# RP2040 register map
Vendor: Raspberry Pi; File version: 0.1
CPU: CM0PLUS r0p1, little endian, MPU, no FPU, VTOR, 2 interrupt priority bits, 26 interrupts
Registers are 32-bit, read-write, reset 0x0 unless marked. A register's access mark holds for its fields unless they carry their own. Offsets are from the block's base; [hi:lo] are bit positions; lines under a group give offsets from that group; {n}, {i} and the like mark numbered series; 'fields as' and 'values as' point back to an identical list; <NAME> marks a mode.

## PADS_BANK0
Base 0x4001C000
0x00 VOLTAGE_SELECT — Voltage select. Per bank control
  [0] VOLTAGE_SELECT
    0=3v3 (Set voltage to 3.3V (DVDD >= 2V5)); 1=1v8 (Set voltage to 1.8V (DVDD <= 1V8))
{0x4+4i} GPIO[{i}] (i=0..29) group
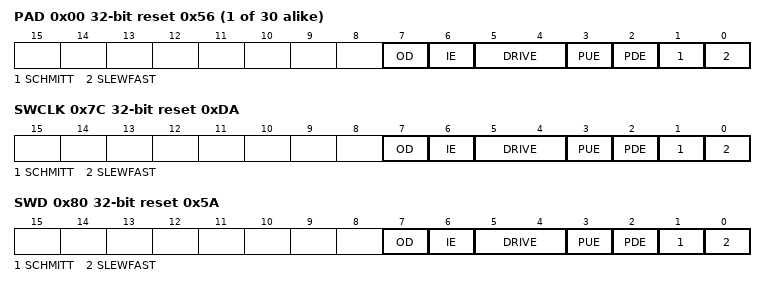
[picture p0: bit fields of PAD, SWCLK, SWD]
  0x00 PAD reset 0x56 — Pad control register
    [7] OD — Output disable. Has priority over output enable from peripherals
    [6] IE — Input enable
    [5:4] DRIVE — Drive strength.
      0=2mA; 1=4mA; 2=8mA; 3=12mA
    [3] PUE — Pull up enable
    [2] PDE — Pull down enable
    [1] SCHMITT — Enable schmitt trigger
    [0] SLEWFAST — Slew rate control. 1 = Fast, 0 = Slow
0x7C SWCLK reset 0xDA — Pad control register
  fields as GPIO[0].PAD
0x80 SWD reset 0x5A — Pad control register
  fields as GPIO[0].PAD

## PADS_QSPI
Base 0x40020000
0x00 VOLTAGE_SELECT — Voltage select. Per bank control
  [0] VOLTAGE_SELECT
    0=3v3 (Set voltage to 3.3V (DVDD >= 2V5)); 1=1v8 (Set voltage to 1.8V (DVDD <= 1V8))
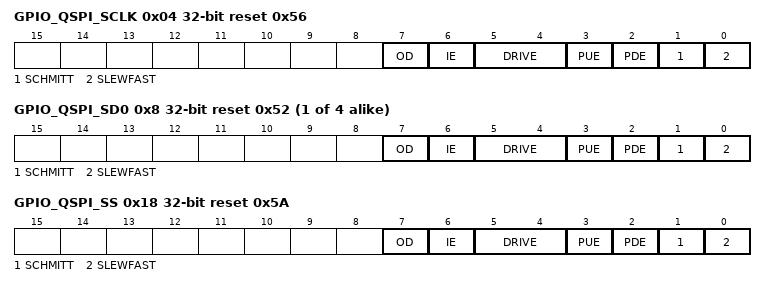
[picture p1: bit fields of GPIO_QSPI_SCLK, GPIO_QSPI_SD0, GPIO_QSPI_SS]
0x04 GPIO_QSPI_SCLK reset 0x56 — Pad control register
  [7] OD — Output disable. Has priority over output enable from peripherals
  [6] IE — Input enable
  [5:4] DRIVE — Drive strength.
    0=2mA; 1=4mA; 2=8mA; 3=12mA
  [3] PUE — Pull up enable
  [2] PDE — Pull down enable
  [1] SCHMITT — Enable schmitt trigger
  [0] SLEWFAST — Slew rate control. 1 = Fast, 0 = Slow
{0x8+4i} GPIO_QSPI_SD{i} reset 0x52 (i=0..3) — Pad control register
  fields as GPIO_QSPI_SCLK
0x18 GPIO_QSPI_SS reset 0x5A — Pad control register
  fields as GPIO_QSPI_SCLK

## XOSC — Controls the crystal oscillator
Base 0x40024000
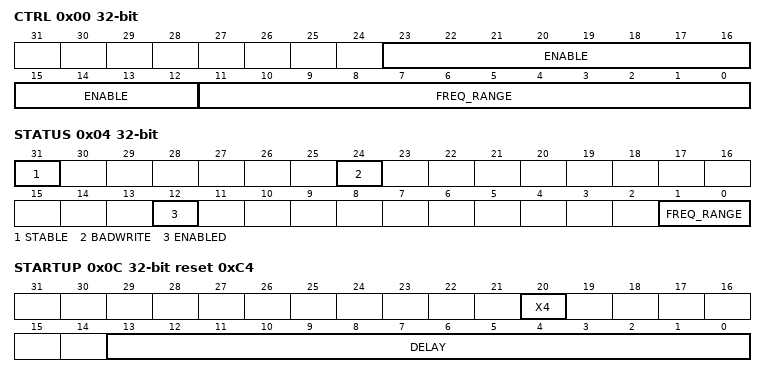
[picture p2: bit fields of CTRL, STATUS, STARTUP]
0x00 CTRL — Crystal Oscillator Control
  [23:12] ENABLE — On power-up this field is initialised to DISABLE and the chip runs from the ROSC. If the chip has subsequently been programmed to run from the XOSC then setting this field to DISABLE may lock-up the chip. If this is a concern then run the clk_ref from the ROSC and enable the clk_sys RESUS feature. The 12-bit code is intended to give some protection against accidental writes. An invalid setting will enable the oscillator.
    0xD1E=DISABLE; 0xFAB=EN
  [11:0] FREQ_RANGE — Frequency range. This resets to 0xAA0 and cannot be changed.
    0xAA0=1_15MHZ
0x04 STATUS access per field — Crystal Oscillator Status
  [31] STABLE ro — Oscillator is running and stable
  [24] BADWRITE rw write-1-clears — An invalid value has been written to CTRL_ENABLE or CTRL_FREQ_RANGE or DORMANT
  [12] ENABLED ro — Oscillator is enabled but not necessarily running and stable, resets to 0
  [1:0] FREQ_RANGE ro — The current frequency range setting, always reads 0
    0=1_15MHZ
0x08 DORMANT — Crystal Oscillator pause control. This is used to save power by pausing the XOSC. On power-up this field is initialised to WAKE. An invalid write will also select WAKE. WARNING: stop the PLLs before selecting dormant mode. WARNING: setup the irq before selecting dormant mode
0x0C STARTUP reset 0xC4 — Controls the startup delay
  [20] X4 — Multiplies the startup_delay by 4. This is of little value to the user given that the delay can be programmed directly.
  [13:0] DELAY — in multiples of 256*xtal_period. The reset value of 0xc4 corresponds to approx 50 000 cycles.
0x1C COUNT — A down counter running at the xosc frequency which counts to zero and stops. To start the counter write a non-zero value. Can be used for short software pauses when setting up time sensitive hardware.
  [7:0] COUNT

## PLL0
Base 0x40028000
Same registers: PLL1 0x4002C000
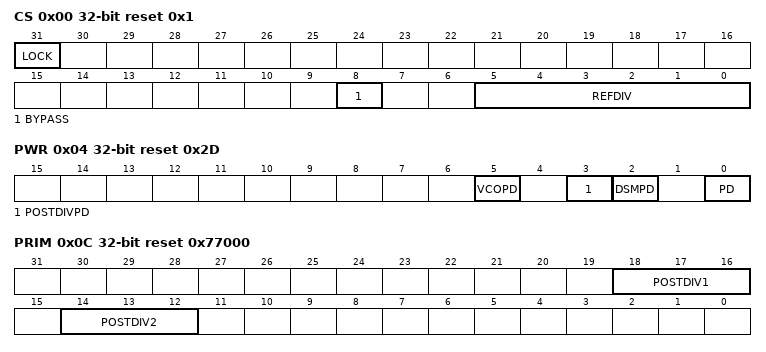
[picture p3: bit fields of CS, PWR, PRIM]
0x00 CS access per field reset 0x1 — Control and Status. GENERAL CONSTRAINTS: Reference clock frequency min=5MHz, max=800MHz. Feedback divider min=16, max=320. VCO frequency min=400MHz, max=1600MHz
  [31] LOCK ro — PLL is locked
  [8] BYPASS rw — Passes the reference clock to the output instead of the divided VCO. The VCO continues to run so the user can switch between the reference clock and the divided VCO but the output will glitch when doing so.
  [5:0] REFDIV rw — Divides the PLL input reference clock. Behaviour is undefined for div=0. PLL output will be unpredictable during refdiv changes, wait for lock=1 before using it.
0x04 PWR reset 0x2D — Controls the PLL power modes.
  [5] VCOPD — PLL VCO powerdown. To save power set high when PLL output not required or bypass=1.
  [3] POSTDIVPD — PLL post divider powerdown. To save power set high when PLL output not required or bypass=1.
  [2] DSMPD — PLL DSM powerdown. Nothing is achieved by setting this low.
  [0] PD — PLL powerdown. To save power set high when PLL output not required.
0x08 FBDIV_INT — Feedback divisor (note: this PLL does not support fractional division)
  [11:0] FBDIV_INT — see ctrl reg description for constraints
0x0C PRIM reset 0x77000 — Controls the PLL post dividers for the primary output (note: this PLL does not have a secondary output) the primary output is driven from VCO divided by postdiv1*postdiv2
  [18:16] POSTDIV1 — divide by 1-7
  [14:12] POSTDIV2 — divide by 1-7
